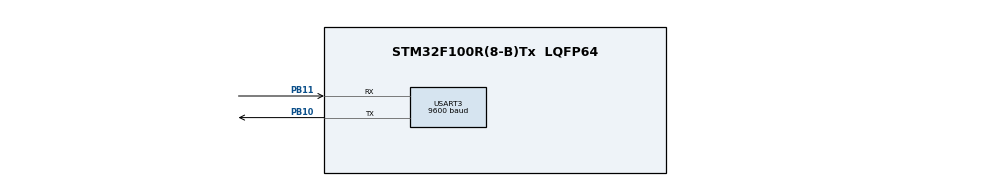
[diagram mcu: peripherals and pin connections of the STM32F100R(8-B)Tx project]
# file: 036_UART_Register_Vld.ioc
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Mcu.Family=STM32F1
Mcu.Name=STM32F100R(8-B)Tx
Mcu.Package=LQFP64
NVIC.PriorityGroup=NVIC_PRIORITYGROUP_4
PA13.Mode=Serial_Wire
PA13.Signal=SYS_JTMS-SWDIO
PA14.Mode=Serial_Wire
PA14.Signal=SYS_JTCK-SWCLK
PB10.Mode=Asynchronous
PB10.Signal=USART3_TX
PB11.Mode=Asynchronous
PB11.Signal=USART3_RX
ProjectManager.HeapSize=0x200
ProjectManager.StackSize=0x400
ProjectManager.TargetToolchain=STM32CubeIDE
RCC.APB1Freq_Value=8000000
RCC.APB2Freq_Value=8000000
USART3.BaudRate=9600
USART3.VirtualMode=VM_ASYNC
board=custom

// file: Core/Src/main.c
/* USER CODE BEGIN Header */
/**
  ******************************************************************************
  * @file           : main.c
  * @brief          : Main program body
  ******************************************************************************
  * @attention
  *
  * Copyright (c) 2024 STMicroelectronics.
  * All rights reserved.
  *
  * This software is licensed under terms that can be found in the LICENSE file
  * in the root directory of this software component.
  * If no LICENSE file comes with this software, it is provided AS-IS.
  *
  ******************************************************************************
  */
/* USER CODE END Header */
#include "main.h"

UART_HandleTypeDef huart3;

/* USER CODE BEGIN PV */
char Rx_Buff[100];
int i=0;

/* USER CODE END PV */

void SystemClock_Config(void);
static void MX_GPIO_Init(void);
static void MX_USART3_UART_Init(void);
/* USER CODE BEGIN PFP */
void RCC_Config(void);
void GPIO_Config(void);
void UART_Config(void);
void NVIC_Config(void);

/* USER CODE END PFP */

/* USER CODE BEGIN 0 */
void RCC_Config(void){

	RCC->CR |= (1<<16);                    			// HSE ON
	while((RCC->CR & (1<<16)) == HAL_OK);				// HSE READY

	RCC->CFGR |= (4 << 18);							// PLL MULTIPL = X6	(FREQ = 24 MHZ)
	RCC->CR |= (0x1080000);							// PLL & CSSON
	RCC->CFGR |= (1 << 1);							// SW = PLL AS SYS. CLK
	RCC->CFGR |= (8 << 4);							// AHB PRESC = /2
	RCC->CFGR &=  ~(1 << 11); 						// APB2 PRESC = NOT DİVİDED
	RCC->CFGR |= (1 << 16); 						// PLL SOURCE = PREDIV1 (HSE)

	RCC->CIR |= (0x0980000);						// CSS PLL HSE READY FLAG RESET

}
void GPIO_Config(void){

	RCC->APB2ENR |= (13 << 0);				// GPIO A & B & AF CLK ENABLE

	GPIOB->CRH |= (9 << 8); 				// GPIOB B10  AF_PP - 10 MHZ
	GPIOB->CRH |= (9 << 12);				// GPIOB B11  AF_PP - 10 MHZ

	AFIO->MAPR &= ~(3 << 4); 				// NO REMAP FOR USART3 (PB10-TX PB11-RX)
}

void UART_Config(void){
	RCC->APB1ENR |= (1 << 16);				// USART3 ENABLE

	USART3->BRR	|=  0x1112; 				// BAUD RATE
	USART3->CR1 |= (1 << 2);				// RX ENABLE
	USART3->CR1 |= (1 << 3);				// TX ENABLE
	USART3->CR1 |= (1 << 5);				// RX INTERRUPT ENABLE
	USART3->CR1 &= ~(1 << 10);				// PARITY DISABLE
	USART3->CR1 &= ~(1 << 12);				// LENGTH: 8 BIT
	USART3->CR1 &= ~(1 << 15); 				// OVER8 BY 16 ( TOLERANCE HIGHER) THAN 8
	USART3->CR2 &= ~(3 << 12); 				// STOP BIT 132

	USART3->CR1 |= (1 << 13);				// USART ENABLE

}
void NVIC_Config(void){
	NVIC->ISER[1]  |= (1 << 7);

}

void USART3_IRQHandler(){

	volatile int str;
	str = USART3->SR;
	Rx_Buff[i] = USART3->DR;
	i++;
}

void Send_Message(char *str){

	while(*str){
		Send_Char(*str);
		str++;
	}
}

void Send_Char(char message){

	while(!(USART3->SR & (1<<7)));					// TXE BUFFER DOLU İSE BEKLE
	USART3->DR = message;
}

/* USER CODE END 0 */

int main(void)
{

  /* USER CODE BEGIN 1 */
	 RCC_Config();
	 GPIO_Config();
	 UART_Config();
	 NVIC_Config();

  /* USER CODE END 1 */

  /* MCU Configuration--------------------------------------------------------*/

  /* Reset of all peripherals, Initializes the Flash interface and the Systick. */
  HAL_Init();

  /* Configure the system clock */
  SystemClock_Config();

  /* Initialize all configured peripherals */
  MX_GPIO_Init();
  MX_USART3_UART_Init();

  /* Infinite loop */
  while (1)
  {

    /* USER CODE BEGIN 3 */

	  Send_Message("HELLO WORLD\n");
	  for(int i = 0; i < 1000000; i++);

  }
  /* USER CODE END 3 */
}

void SystemClock_Config(void)
{
  RCC_OscInitTypeDef RCC_OscInitStruct = {0};
  RCC_ClkInitTypeDef RCC_ClkInitStruct = {0};

  /** Initializes the RCC Oscillators according to the specified parameters
  * in the RCC_OscInitTypeDef structure.
  */
  RCC_OscInitStruct.OscillatorType = RCC_OSCILLATORTYPE_HSI;
  RCC_OscInitStruct.HSIState = RCC_HSI_ON;
  RCC_OscInitStruct.HSICalibrationValue = RCC_HSICALIBRATION_DEFAULT;
  RCC_OscInitStruct.PLL.PLLState = RCC_PLL_NONE;
  if (HAL_RCC_OscConfig(&RCC_OscInitStruct) != HAL_OK)
  {
    Error_Handler();
  }

  /** Initializes the CPU, AHB and APB buses clocks
  */
  RCC_ClkInitStruct.ClockType = RCC_CLOCKTYPE_HCLK|RCC_CLOCKTYPE_SYSCLK
                              |RCC_CLOCKTYPE_PCLK1|RCC_CLOCKTYPE_PCLK2;
  RCC_ClkInitStruct.SYSCLKSource = RCC_SYSCLKSOURCE_HSI;
  RCC_ClkInitStruct.AHBCLKDivider = RCC_SYSCLK_DIV1;
  RCC_ClkInitStruct.APB1CLKDivider = RCC_HCLK_DIV1;
  RCC_ClkInitStruct.APB2CLKDivider = RCC_HCLK_DIV1;

  if (HAL_RCC_ClockConfig(&RCC_ClkInitStruct, FLASH_LATENCY_0) != HAL_OK)
  {
    Error_Handler();
  }
}

static void MX_USART3_UART_Init(void)
{

  huart3.Instance = USART3;
  huart3.Init.BaudRate = 9600;
  huart3.Init.WordLength = UART_WORDLENGTH_8B;
  huart3.Init.StopBits = UART_STOPBITS_1;
  huart3.Init.Parity = UART_PARITY_NONE;
  huart3.Init.Mode = UART_MODE_TX_RX;
  huart3.Init.HwFlowCtl = UART_HWCONTROL_NONE;
  huart3.Init.OverSampling = UART_OVERSAMPLING_16;
  if (HAL_UART_Init(&huart3) != HAL_OK)
  {
    Error_Handler();
  }

}

static void MX_GPIO_Init(void)
{

  /* GPIO Ports Clock Enable */
  __HAL_RCC_GPIOB_CLK_ENABLE();
  __HAL_RCC_GPIOA_CLK_ENABLE();

}

void Error_Handler(void)
{
  __disable_irq();
  while (1)
  {
  }
}
